# V32F20x_CM33 register map
File version: 1.0.3
CPU: CM33 r0p4, little endian, MPU, FPU, DSP, 3 interrupt priority bits, 8 SAU regions
Registers are 32-bit, read-write, reset 0x0 unless marked. A register's access mark holds for its fields unless they carry their own. Offsets are from the block's base; [hi:lo] are bit positions.

## I2S0 — I2S0 Peripheral Interface
Base 0x40083000
Same registers: I2S1 0x40083800, SEC_I2S0 0x50083000, SEC_I2S1 0x50083800
0x00 IER — I2S Enable Register.
  [0] IEN — This bit enables or disables I2S
0x04 IRER — I2S Receiver Block Enable Register.
  [0] RXEN — This bit enables or disables the receiver.
0x08 ITER wo — I2S Transmitter Block Enable Register.
  [0] TXEN — This bit enables or disables the transmitter
0x0C CER — Clock Enable Register.
  [0] CLKEN — This bit enables disables the clock generation signals sclk_en ws_out and sclk_gate
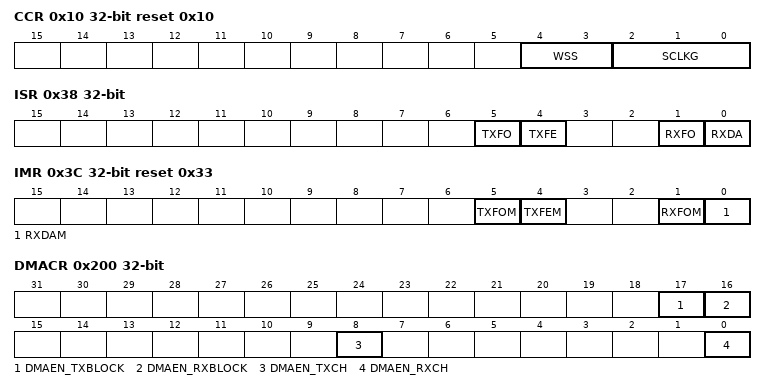
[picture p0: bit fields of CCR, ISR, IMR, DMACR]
0x10 CCR reset 0x10 — Clock Configuration Register.
  [4:3] WSS — These bits are used to program the number of sclk cycles for which the word select line ws_out stays in the left or right sample mode
  [2:0] SCLKG — These bits are used to program the gating of sclk
0x14 RXFFR wo — Receiver Block FIFO Reset Register.
  [0] RXFFR — Writing a 1 to this register flushes all the RX FIFOs this is a self clearing bit
0x18 TXFFR wo — Transmitter Block FIFO Reset Register.
  [0] TXFFR — Writing a 1 to this register flushes all the TX FIFOs this is a self clearing bit
0x20 LRBR ro — Left Receive Buffer Register.
  [31:0] LRBR — The left stereo data received serially from the receive channel input sdix
0x20 LTHR wo (alternate view of LRBR) — Left Transmit Holding Register.
  [31:0] LTHR — The left stereo data to be transmitted serially through the transmit channel output sdox is written through this register
0x24 RRBR ro — Right Receive Buffer Register.
  [31:0] RRBR — The right stereo data received serially from the receive channel input sdix is read through this register
0x24 RTHR wo (alternate view of RRBR) — This specifies the Right Transmit Holding Register
  [31:0] RTHR — The right stereo data to be transmitted serially through the transmit channel output sdox is written through this register
0x28 RER reset 0x1 — Receive Enable Register.
  [0] RXCHEN — Receive channel enable
0x2C TER — Transmit Enable Register.
  [0] TXCHEN — Transmit channel enable
0x30 RCR reset 0x5 — Receive Configuration Register.
  [2:0] WLEN — These bits are used to program the desired data resolution of the receiver and enables the LSB of the incoming left or right word to be placed in the LSB of the LRBRx or RRBRx register
0x34 TCR reset 0x5 — Transmit Configuration Register.
  [2:0] WLEN — These bits are used to program the data resolution of the transmitter and ensures the MSB of the data is transmitted first
0x38 ISR ro — Interrupt status Register.
  [5] TXFO — This bit specifies whether the TX FIFO write is valid or an overrun
  [4] TXFE — Status of Transmit Empty Trigger interrupt.
  [1] RXFO — Status of Data Overrun interrupt for the RX channel
  [0] RXDA — Status of Receive Data Available interrupt
0x3C IMR reset 0x33 — Interrupt Mask Register.
  [5] TXFOM — Mask TX FIFO Overrun interrupt.
  [4] TXFEM — Mask TX FIFO Empty interrupt.
  [1] RXFOM — Mask RX FIFO Overrun interrupt.
  [0] RXDAM — Mask RX FIFO Data Available interrupt.
0x40 ROR ro — Receive Overrun Register.
  [0] RXCHO — Read this bit to clear the RX FIFO Data Overrun interrupt
0x44 TOR ro — Transmit Overrun Register.
  [0] TXCHO — Read this bit to clear the TX FIFO Data Overrun interrupt
0x48 RFCR — Receive FIFO Configuration Register.
  [3:0] RXCHDT — These bits program the trigger level in the RX FIFO at which the Received Data Available interrupt and DMA request is generated
0x4C TFCR — Transmit FIFO Configuration Register.
  [3:0] TXCHET — These bits program the trigger level in the TX FIFO at which the Empty Threshold Reached Interrupt and DMA request is generated
0x50 RFF wo — Receive FIFO Flush Register.
  [0] RXCHFR — Receive Channel FIFO Reset.
0x54 TFF wo — Transmit FIFO Flush Register.
  [0] TXCHFR — Transmit Channel FIFO Reset.
0x1C0 RXDMA ro — Receiver Block DMA Register.
  [31:0] RXDMA — These bits are used to cycle repeatedly through the enabled receive channels from lowest numbered to highest reading stereo data pairs
0x1C8 TXDMA wo — Transmitter Block DMA Register.
0x200 DMACR — DMA Control Register.
  [17] DMAEN_TXBLOCK — DMA Enable for transmit block
  [16] DMAEN_RXBLOCK — DMA Enable for receive block
  [8] DMAEN_TXCH — DMA Enable for transmit channel
  [0] DMAEN_RXCH — DMA Enable for receive channel
